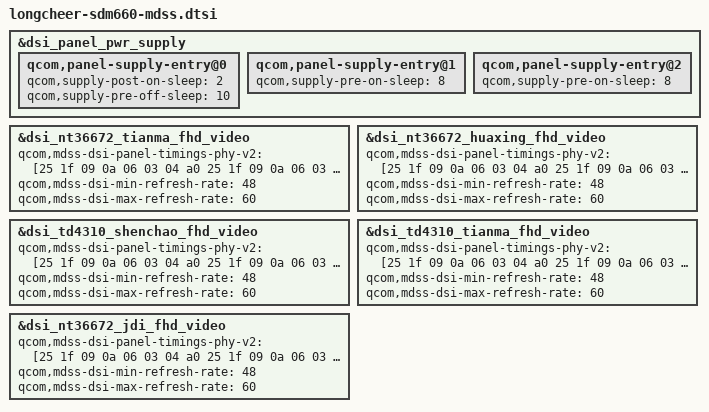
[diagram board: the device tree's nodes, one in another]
/* Copyright (c) 2019, The Linux Foundation. All rights reserved.
 *
 * This program is free software; you can redistribute it and/or modify
 * it under the terms of the GNU General Public License version 2 and
 * only version 2 as published by the Free Software Foundation.
 *
 * This program is distributed in the hope that it will be useful,
 * but WITHOUT ANY WARRANTY; without even the implied warranty of
 * MERCHANTABILITY or FITNESS FOR A PARTICULAR PURPOSE.  See the
 * GNU General Public License for more details.
 */
#include "display/dsi-panel-huaxing-nt36672-1080p-video.dtsi"
#include "display/dsi-panel-tianma-nt36672-1080p-video.dtsi"
#include "display/dsi-panel-jdi-nt36672-1080p-video.dtsi"
#include "display/dsi-panel-shenchao-td4310-1080p-video.dtsi"
#include "display/dsi-panel-tianma-td4310-1080p-video.dtsi"

/* sdm660-mdss-panels.dtsi common diff */
&dsi_panel_pwr_supply {
	qcom,panel-supply-entry@0 {
		qcom,supply-post-on-sleep = <2>;
		qcom,supply-pre-off-sleep = <10>;
	};

	qcom,panel-supply-entry@1 {
		qcom,supply-pre-on-sleep = <8>;
	};

	qcom,panel-supply-entry@2 {
		qcom,supply-pre-on-sleep = <8>;
	};
};

&dsi_nt36672_tianma_fhd_video {
	qcom,mdss-dsi-panel-timings-phy-v2 = [25 1f 09 0a 06 03 04 a0
		25 1f 09 0a 06 03 04 a0
		25 1f 09 0a 06 03 04 a0
		25 1f 09 0a 06 03 04 a0
		25 1e 08 0a 06 03 04 a0];
	qcom,mdss-dsi-min-refresh-rate = <48>;
	qcom,mdss-dsi-max-refresh-rate = <60>;
};

 &dsi_nt36672_huaxing_fhd_video {
	qcom,mdss-dsi-panel-timings-phy-v2 = [25 1f 09 0a 06 03 04 a0
		25 1f 09 0a 06 03 04 a0
		25 1f 09 0a 06 03 04 a0
		25 1f 09 0a 06 03 04 a0
		25 1e 08 0a 06 03 04 a0];
	qcom,mdss-dsi-min-refresh-rate = <48>;
	qcom,mdss-dsi-max-refresh-rate = <60>;
};

 &dsi_td4310_shenchao_fhd_video {
	qcom,mdss-dsi-panel-timings-phy-v2 = [25 1f 09 0a 06 03 04 a0
		25 1f 09 0a 06 03 04 a0
		25 1f 09 0a 06 03 04 a0
		25 1f 09 0a 06 03 04 a0
		25 1e 08 0a 06 03 04 a0];
	qcom,mdss-dsi-min-refresh-rate = <48>;
	qcom,mdss-dsi-max-refresh-rate = <60>;
};

 &dsi_td4310_tianma_fhd_video {
	qcom,mdss-dsi-panel-timings-phy-v2 = [25 1f 09 0a 06 03 04 a0
		25 1f 09 0a 06 03 04 a0
		25 1f 09 0a 06 03 04 a0
		25 1f 09 0a 06 03 04 a0
		25 1f 08 0a 06 03 04 a0];
	qcom,mdss-dsi-min-refresh-rate = <48>;
	qcom,mdss-dsi-max-refresh-rate = <60>;
};

 &dsi_nt36672_jdi_fhd_video {
	qcom,mdss-dsi-panel-timings-phy-v2 = [25 1f 09 0a 06 03 04 a0
		25 1f 09 0a 06 03 04 a0
		25 1f 09 0a 06 03 04 a0
		25 1f 09 0a 06 03 04 a0
		25 1e 08 0a 06 03 04 a0];
	qcom,mdss-dsi-min-refresh-rate = <48>;
	qcom,mdss-dsi-max-refresh-rate = <60>;
};
